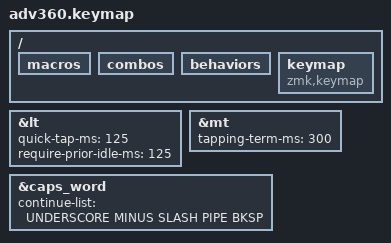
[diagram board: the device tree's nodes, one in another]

// === ZMK STANDARD INCLUDES ===
#include <dt-bindings/zmk/keys.h>
#include <dt-bindings/zmk/bt.h>
#include <dt-bindings/zmk/rgb.h>
#include <dt-bindings/zmk/backlight.h>
#include <dt-bindings/zmk/stp.h>
#include <dt-bindings/zmk/pointing.h>
#include <behaviors.dtsi>   // ZMK standard behaviors (lt, mt, caps_word, etc.) — must stay
#include "adv360_key_numbers.dtsi"

// === LAYER NUMBER DEFINES ===
/* LED layer colors:  0 ⚫   1 ⚪   2 🔵   3 🟢   4 🔴   5 🟣   6 🩵   7 🟡   8 ⚫   9 ⚫*/
/*                    NGM      LR     EDT    NUM     UTL    FNC     LET    CAP    QRT    kp#   */
#define L_0 0
#define L_NGM 0     // engram
#define L_LR 1      // Lightroom
#define L_EDT 2     // edit (mostly LH while RH uses mouse, or general use)
#define L_NUM 3     // numpad
#define L_UTL 4     // utils
#define L_FNC 5     // function keys 1-12 (like numpad)
#define L_LET 6     // plain letters - mirroring NGM - so can use the "hold-for-accents" utility
#define L_CAP 7     // CAPs layer for constant Shift+ but keeping many things "unshifted" esp some symbols
#define L_QRT 8     // Qwerty-ish; like for games
#define L_KP 9      // keypad (*actual KP key codes) (in case ever need)
#define L_NAV 10    // navigation (arrows, home/end, pg-up/dn)

// === GLOBAL KEY SHORTHANDS ===
// Helpers for common key-defaults (block [&none] or passthrough [&trans])
#define ___ &trans
#define _x_ &none
#define _tbd_ &none
#define nil 0

// === ZMK BEHAVIOR DEFAULTS ===
/* TAPPING timeouts, flavors, etc.
    try disable global-quick-tap, & set quick-tap-ms faster like 125
    one suggested like 75 for the "global-quick-tap-ms" [which seems maybe new/ish]
    try remove 'hold trigger' positions to see
        so far seems better; maybe the #-key array is off? - [] how to test?
*/

// Layer tap defaults?
&lt {
    quick-tap-ms = <125>;  /* was 300 */
    require-prior-idle-ms = <125>;  // replaces deprecated global-quick-tap
};

// Mod-tap defaults?
&mt {
    tapping-term-ms = <300>;
};

// capsWORD symbols accepted list overrides (additional ones to NOT disrupt). These are my prefs for mostly business, not coding, use-cases.
&caps_word {
    continue-list = <UNDERSCORE MINUS SLASH PIPE BKSP>;
};


/ {
    macros {
        #include "user/macros/general_macros.dtsi"
        #include "user/macros/shortcuts_macros.dtsi"
        #include "user/macros/hold_mods_delays.dtsi"
        #include "user/macros/combos_macros_for_holds.dtsi"
    };

    combos {
        #include "user/combos.dtsi"
    };

    behaviors {
        #include "version.dtsi"
        #include "user/def_macros.dtsi"
        #include "user/tapdance/general_tapdance.dtsi"
        #include "user/tapdance/lightroom_tapdance.dtsi"
        #include "user/behaviors/mod_morphs_general.dtsi"
        #include "user/behaviors/mod_morphs_engram.dtsi"
        #include "user/behaviors/mod_morphs_nums.dtsi"
        #include "user/behaviors/holdtaps_for_layers.dtsi"
        #include "user/behaviors/holdtaps_special_and_combos.dtsi"
    };

    keymap {
        compatible = "zmk,keymap";
        #include "user/layers/layer_0_NGM.dtsi"
        #include "user/layers/layer_1_LR.dtsi"
        #include "user/layers/layer_2_EDT.dtsi"
        #include "user/layers/layer_3_NUM.dtsi"
        #include "user/layers/layer_4_UTL.dtsi"
        #include "user/layers/layer_5_FNC.dtsi"
        #include "user/layers/layer_6_LET.dtsi"
        #include "user/layers/layer_7_CAP.dtsi"
        #include "user/layers/layer_8_QRT.dtsi"
        #include "user/layers/layer_9_KP.dtsi"
        #include "user/layers/layer_10_NAV.dtsi"
    };
};
